# AES_Accelerator_2 register map
Vendor: Texas Instruments
Peripheral module from a debugger description file (folder msp430).
Registers are 16-bit, access not given, no defined reset value unless marked. A register's access mark holds for its fields unless they carry their own. Offsets are as the file gives them; lines under a group give offsets from that group; [hi:lo] are bit positions; {n}, {i} and the like mark numbered series; 'fields as' and 'values as' point back to an identical list; <NAME> marks a mode.

## AES_Accelerator
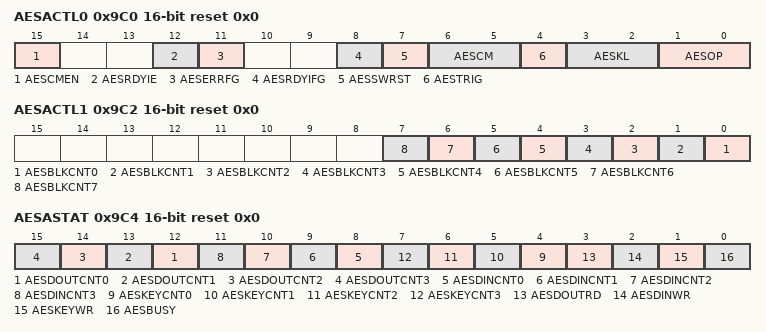
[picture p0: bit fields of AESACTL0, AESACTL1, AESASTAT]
0x9C0 AESACTL0 rw reset 0x0 — AES accelerator control register 0
  [15] AESCMEN — AES DMA cipher mode enable
  [12] AESRDYIE — AES ready interrupt enable
  [11] AESERRFG — AES Error Flag
  [8] AESRDYIFG — AES ready interrupt flag
  [7] AESSWRST — AES Software Reset
  [6:5] AESCM — AES Cipher mode select Bit: 0
    0=AES Cipher mode select: ECB; 1=AES Cipher mode select: CBC; 2=AES Cipher mode select: OFB; 3=AES Cipher mode select: CFB
  [4] AESTRIG — AES Trigger Select
  [3:2] AESKL — AES Key length Bit: 0
    0=AES Key length: AES128; 1=AES Key length: AES192; 2=AES Key length: AES256
  [1:0] AESOP — AES Operation Bit: 0
    0=AES Operation: Encrypt; 1=AES Operation: Decrypt (same Key); 2=AES Operation: Decrypt (frist round Key); 3=AES Operation: Generate first round Key
0x9C2 AESACTL1 rw reset 0x0 — AES accelerator control register 1
  [n] AESBLKCNT{n} (n=0..7) — AES Cipher Block Counter Bit: {n}
0x9C4 AESASTAT rw reset 0x0 — AES accelerator status register
  [n+12] AESDOUTCNT{n} (n=0..3) — AES Bytes read via AESADOUT Bit: {n}
  [n+8] AESDINCNT{n} (n=0..3) — AES Bytes written via AESADIN Bit: {n}
  [n+4] AESKEYCNT{n} (n=0..3) — AES Bytes written via AESAKEY Bit: {n}
  [3] AESDOUTRD — AES All 16 bytes read from AESADOUT
  [2] AESDINWR — AES All 16 bytes written to AESADIN
  [1] AESKEYWR — AES All 16 bytes written to AESAKEY
  [0] AESBUSY
0x9C6 AESAKEY — AES accelerator key register
0x9C8 AESADIN — AES accelerator data in register
0x9CA AESADOUT — AES accelerator data out register
0x9CC AESAXDIN — AES accelerator XORed data in register
0x9CE AESAXIN — AES accelerator XORed data in register (no trigger)
